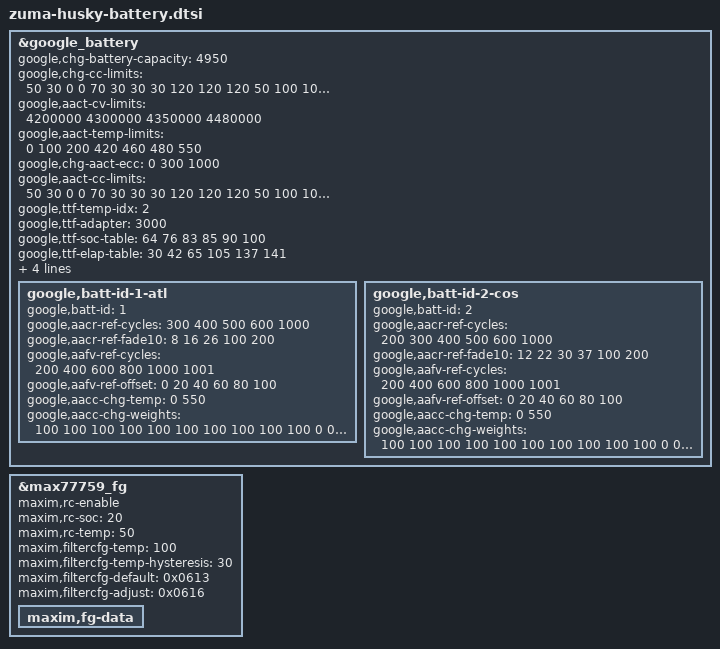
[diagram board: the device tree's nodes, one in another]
// SPDX-License-Identifier: GPL-2.0-only
/*
 * Battery device tree entries specific to panther
 *
 * Copyright 2022 Google,LLC
 *
 */

&google_battery {
	google,chg-battery-capacity = <4950>;
	google,chg-cc-limits = <
               50   30    0   0
               70   30   30  30
              120  120  120  50
              100  100  100  50
               50   50    0   0
               30    0    0   0
	>;

	google,aact-cv-limits = <4200000 4300000 4350000 4480000>;
	google,aact-temp-limits = <0 100 200 420 460 480 550>;
	google,chg-aact-ecc = <0 300 1000>;
	google,aact-cc-limits = <
               50   30    0   0
               70   30   30  30
              120  120  120  50
              100  100  100  50
               50   50    0   0
               30    0    0   0
               50   30    0   0
               70   30   30  30
              110  110  110  50
              100  100  100  50
               50   50    0   0
               30    0    0   0
               50   30    0   0
               70   30   30  30
              100  100  100  50
              100  100  100  50
               50   50    0   0
               30    0    0   0
	>;

	google,ttf-temp-idx= <2>;
	google,ttf-adapter = <3000>;
	google,ttf-soc-table =  <64 76 83 85  90  100>;
	google,ttf-elap-table = <30 42 65 105 137 141>;
	google,ttf-tier-table = <0 67 79>;

	/* 90% after 600 cycles, 80% after 1000 cycles */
	google,aacr-algo = <3>;
	google,aacr-cliff-capacity-rate = <80>;
	google,aacr-cycle-max = <1000>;

	google,batt-id-1-atl {
		google,batt-id = <1>;
		google,aacr-ref-cycles = <300 400 500 600 1000>;
		google,aacr-ref-fade10 = <  8  16  26 100  200>;
		google,aafv-ref-cycles = <200 400 600 800 1000 1001>;
		google,aafv-ref-offset = <  0  20  40  60   80  100>;
		google,aacc-chg-temp = <0 550>;
		google,aacc-chg-weights = < /* units: 1/1000 cycles */
			100 100 100 100 100 100 100 100 100 100 /* soc:  1 ~  10, temp_idx: 0 */
			  0   0   0   0   0   0   0   0   0   0 /* soc: 11 ~  20, temp_idx: 0 */
			  0   0   0   0   0   0   0   0   0   0 /* soc: 21 ~  30, temp_idx: 0 */
			  0   0   0   0   0   0   0   0   0   0 /* soc: 31 ~  40, temp_idx: 0 */
			  0   0   0   0   0   0   0   0   0   0 /* soc: 41 ~  50, temp_idx: 0 */
			  0   0   0   0   0   0   0   0   0   0 /* soc: 51 ~  60, temp_idx: 0 */
			  0   0   0   0   0   0   0   0   0   0 /* soc: 61 ~  70, temp_idx: 0 */
			  0   0   0   0   0   0   0   0   0   0 /* soc: 71 ~  80, temp_idx: 0 */
			  0   0   0   0   0   0   0   0   0   0 /* soc: 81 ~  90, temp_idx: 0 */
			  0   0   0   0   0   0   0   0   0   0 /* soc: 91 ~ 100, temp_idx: 0 */
		>;
	};

	google,batt-id-2-cos {
		google,batt-id = <2>;
		google,aacr-ref-cycles = <200 300 400 500 600 1000>;
		google,aacr-ref-fade10 = < 12  22  30  37 100  200>;
		google,aafv-ref-cycles = <200 400 600 800 1000 1001>;
		google,aafv-ref-offset = <  0  20  40  60   80  100>;
		google,aacc-chg-temp = <0 550>;
		google,aacc-chg-weights = < /* units: 1/1000 cycles */
			100 100 100 100 100 100 100 100 100 100 /* soc:  1 ~  10, temp_idx: 0 */
			  0   0   0   0   0   0   0   0   0   0 /* soc: 11 ~  20, temp_idx: 0 */
			  0   0   0   0   0   0   0   0   0   0 /* soc: 21 ~  30, temp_idx: 0 */
			  0   0   0   0   0   0   0   0   0   0 /* soc: 31 ~  40, temp_idx: 0 */
			  0   0   0   0   0   0   0   0   0   0 /* soc: 41 ~  50, temp_idx: 0 */
			  0   0   0   0   0   0   0   0   0   0 /* soc: 51 ~  60, temp_idx: 0 */
			  0   0   0   0   0   0   0   0   0   0 /* soc: 61 ~  70, temp_idx: 0 */
			  0   0   0   0   0   0   0   0   0   0 /* soc: 71 ~  80, temp_idx: 0 */
			  0   0   0   0   0   0   0   0   0   0 /* soc: 81 ~  90, temp_idx: 0 */
			  0   0   0   0   0   0   0   0   0   0 /* soc: 91 ~ 100, temp_idx: 0 */
		>;
	};
};

&max77759_fg {
	maxim,rc-enable;
	maxim,rc-soc = <20>;
	maxim,rc-temp = <50>;

	maxim,filtercfg-temp = <100>;
	maxim,filtercfg-temp-hysteresis = <30>;
	maxim,filtercfg-default = /bits/ 16 <0x0613>;
	maxim,filtercfg-adjust = /bits/ 16 <0x0616>;

	maxim,fg-data {
		#include "zuma-husky-battery-data.dtsi"
	};
};
